# ESP32-S31 register map
Vendor: ESPRESSIF SYSTEMS (SHANGHAI) CO., LTD.; Series: ESP32 S-Series; File version: 1
CPU: RV32IMAFC r0p0, little endian, no MPU, FPU, 0 interrupt priority bits
Address unit: 32 bits
Registers are 32-bit, read-write, reset 0x0 unless marked. A register's access mark holds for its fields unless they carry their own. Offsets are from the block's base; [hi:lo] are bit positions; {n}, {i} and the like mark numbered series.

## SPI0 (part 2 of 2) — SPI (Serial Peripheral Interface) Controller 0
Base 0x20500000
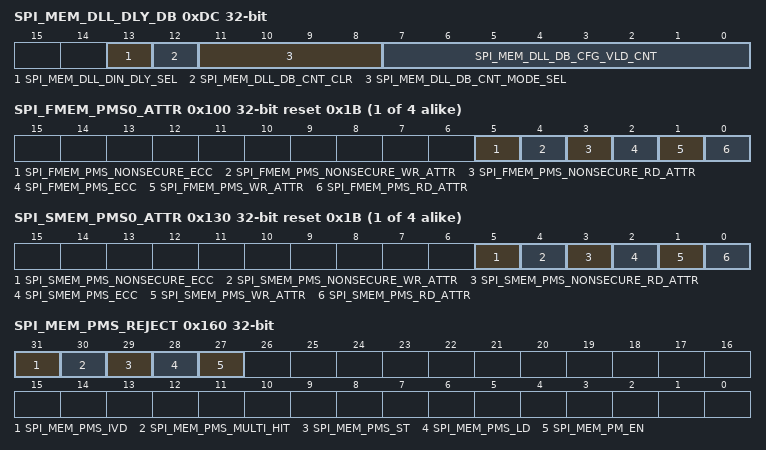
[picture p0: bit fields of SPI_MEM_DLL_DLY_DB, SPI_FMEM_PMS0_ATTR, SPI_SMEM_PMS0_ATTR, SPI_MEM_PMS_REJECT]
0xDC SPI_MEM_DLL_DLY_DB — MSPI DLL function and debug configuration register
  [13] SPI_MEM_DLL_DIN_DLY_SEL — Configures the din channel. 1: Use delayed data. 0: Do not use delayed data.
  [12] SPI_MEM_DLL_DB_CNT_CLR — Configures the start time of the debug window. 1: Clear db_vld_cnt to 0 and Get ready for debug. 0: No debug.
  [11:8] SPI_MEM_DLL_DB_CNT_MODE_SEL — [3]:1-spi_din[15:8]. 0-spi_din[7:0]. [2]:1-only shift wptr or rptr. 0-both shft wptr and rptr. [1]:1-wprt[3:0] and rptr[3:0]. 0-rptr[3:0] and wprt[3:0]. [0]:1-neg_ptr[3:0]. 0-pos_prt[3:0].
  [7:0] SPI_MEM_DLL_DB_CFG_VLD_CNT — Configures the end time of the debug window.
0xE0 SPI_MEM_DLL_DB_ST0 ro — MSPI DLL debug status0 register
  [31:0] SPI_MEM_DB_FIFO_CNT_H — Debug for DLL FIFO pointer. Use a 64bits shift register to record pointer changes during the debug window. db_fifo_cnt[63:32]
0xE4 SPI_MEM_DLL_DB_ST1 ro — MSPI DLL debug status1 register
  [31:0] SPI_MEM_DB_FIFO_CNT_L — Debug for DLL FIFO pointer. Use a 64bits shift register to record pointer changes during the debug window. db_fifo_cnt[31:0]
{0x100+4i} SPI_FMEM_PMS{i}_ATTR (i=0..3) reset 0x1B — SPI1 flash PMS section {i} attribute register
  [5] SPI_FMEM_PMS_NONSECURE_ECC — SPI1 flash non-secure PMS section %s ECC mode, 1: enable ECC mode. 0: Disable it. The flash PMS section %s is configured by registers SPI_FMEM_PMS%s_ADDR_REG and SPI_FMEM_PMS%s_SIZE_REG.
  [4] SPI_FMEM_PMS_NONSECURE_WR_ATTR — 1: SPI1 flash non-secure PMS section %s write accessible. 0: Not allowed.
  [3] SPI_FMEM_PMS_NONSECURE_RD_ATTR — 1: SPI1 flash non-secure PMS section %s read accessible. 0: Not allowed.
  [2] SPI_FMEM_PMS_ECC — SPI1 flash PMS section %s ECC mode, 1: enable ECC mode. 0: Disable it. The flash PMS section %s is configured by registers SPI_FMEM_PMS%s_ADDR_REG and SPI_FMEM_PMS%s_SIZE_REG.
  [1] SPI_FMEM_PMS_WR_ATTR — 1: SPI1 flash PMS section %s write accessible. 0: Not allowed.
  [0] SPI_FMEM_PMS_RD_ATTR — 1: SPI1 flash PMS section %s read accessible. 0: Not allowed.
{0x110+4i} SPI_FMEM_PMS{i}_ADDR (i=0..3) — SPI1 flash PMS section {i} start address register
  [28:0] S — SPI1 flash PMS section %s start address value
{0x120+4i} SPI_FMEM_PMS{i}_SIZE (i=0..3) reset 0x1000 — SPI1 flash PMS section {i} start address register
  [16:0] SPI_FMEM_PMS_SIZE — SPI1 flash PMS section %s address region is (SPI_FMEM_PMS%s_ADDR_S, SPI_FMEM_PMS%s_ADDR_S + SPI_FMEM_PMS%s_SIZE)
{0x130+4i} SPI_SMEM_PMS{i}_ATTR (i=0..3) reset 0x1B — SPI1 external RAM PMS section {i} attribute register
  [5] SPI_SMEM_PMS_NONSECURE_ECC — SPI1 external RAM non-secure PMS section %s ECC mode, 1: enable ECC mode. 0: Disable it. The external RAM PMS section %s is configured by registers SPI_SMEM_PMS%s_ADDR_REG and SPI_SMEM_PMS%s_SIZE_REG.
  [4] SPI_SMEM_PMS_NONSECURE_WR_ATTR — 1: SPI1 external RAM non-secure PMS section %s write accessible. 0: Not allowed.
  [3] SPI_SMEM_PMS_NONSECURE_RD_ATTR — 1: SPI1 external RAM non-secure PMS section %s read accessible. 0: Not allowed.
  [2] SPI_SMEM_PMS_ECC — SPI1 external RAM PMS section %s ECC mode, 1: enable ECC mode. 0: Disable it. The external RAM PMS section %s is configured by registers SPI_SMEM_PMS%s_ADDR_REG and SPI_SMEM_PMS%s_SIZE_REG.
  [1] SPI_SMEM_PMS_WR_ATTR — 1: SPI1 external RAM PMS section %s write accessible. 0: Not allowed.
  [0] SPI_SMEM_PMS_RD_ATTR — 1: SPI1 external RAM PMS section %s read accessible. 0: Not allowed.
{0x140+4i} SPI_SMEM_PMS{i}_ADDR (i=0..3) — SPI1 external RAM PMS section {i} start address register
  [28:0] S — SPI1 external RAM PMS section %s start address value
{0x150+4i} SPI_SMEM_PMS{i}_SIZE (i=0..3) reset 0x1000 — SPI1 external RAM PMS section {i} start address register
  [16:0] SPI_SMEM_PMS_SIZE — SPI1 external RAM PMS section %s address region is (SPI_SMEM_PMS%s_ADDR_S, SPI_SMEM_PMS%s_ADDR_S + SPI_SMEM_PMS%s_SIZE)
0x160 SPI_MEM_PMS_REJECT access per field — SPI1 access reject register
  [31] SPI_MEM_PMS_IVD ro — 1: SPI1 access is rejected because of address multi-hit. 0: No address multi-hit error. It is cleared by when SPI_MEM_PMS_REJECT_INT_CLR bit is set.
  [30] SPI_MEM_PMS_MULTI_HIT ro — 1: SPI1 access is rejected because of address miss. 0: No address miss error. It is cleared by when SPI_MEM_PMS_REJECT_INT_CLR bit is set.
  [29] SPI_MEM_PMS_ST ro — 1: SPI1 read access error. 0: No read access error. It is cleared by when SPI_MEM_PMS_REJECT_INT_CLR bit is set.
  [28] SPI_MEM_PMS_LD ro — 1: SPI1 write access error. 0: No write access error. It is cleared by when SPI_MEM_PMS_REJECT_INT_CLR bit is set.
  [27] SPI_MEM_PM_EN rw — Set this bit to enable SPI0/1 transfer permission control function.
0x164 SPI_MEM_PMS_REJECT_ADDR ro — SPI1 access reject addr register
  [28:0] SPI_MEM_REJECT_ADDR — This bits show the first SPI1 access error address. It is cleared by when SPI_MEM_PMS_REJECT_INT_CLR bit is set.
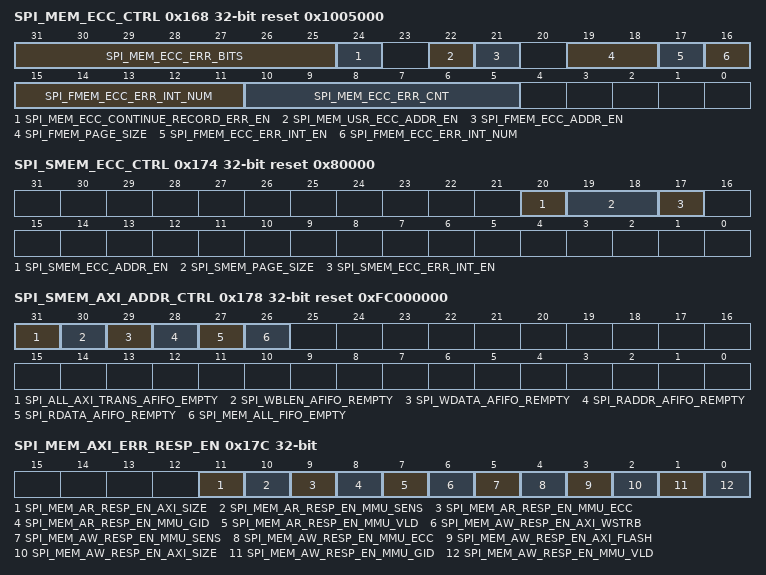
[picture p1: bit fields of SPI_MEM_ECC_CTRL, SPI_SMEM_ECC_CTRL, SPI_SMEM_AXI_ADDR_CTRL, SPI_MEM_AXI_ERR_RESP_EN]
0x168 SPI_MEM_ECC_CTRL access per field reset 0x1005000 — MSPI ECC control register
  [31:25] SPI_MEM_ECC_ERR_BITS ro — Records the first ECC error bit number in the 16 bytes(From 0~127, corresponding to byte 0 bit 0 to byte 15 bit 7)
  [24] SPI_MEM_ECC_CONTINUE_RECORD_ERR_EN rw — 1: The error information in SPI_MEM_ECC_ERR_BITS and SPI_MEM_ECC_ERR_ADDR is updated when there is an ECC error. 0: SPI_MEM_ECC_ERR_BITS and SPI_MEM_ECC_ERR_ADDR record the first ECC error information.
  [22] SPI_MEM_USR_ECC_ADDR_EN rw — Set this bit to enable ECC address convert in SPI0/1 USR_CMD transfer.
  [21] SPI_FMEM_ECC_ADDR_EN rw — Set this bit to enable MSPI ECC address conversion, no matter MSPI accesses to the ECC region or non-ECC region of flash. If there is no ECC region in flash, this bit should be 0. Otherwise, this bit should be 1.
  [19:18] SPI_FMEM_PAGE_SIZE rw — Set the page size of the flash accessed by MSPI. 0: 256 bytes. 1: 512 bytes. 2: 1024 bytes. 3: 2048 bytes.
  [17] SPI_FMEM_ECC_ERR_INT_EN rw — Set this bit to calculate the error times of MSPI ECC read when accesses to flash.
  [16:11] SPI_FMEM_ECC_ERR_INT_NUM rw — Set the error times of MSPI ECC read to generate MSPI SPI_MEM_ECC_ERR_INT interrupt.
  [10:5] SPI_MEM_ECC_ERR_CNT ro — This bits show the error times of MSPI ECC read. It is cleared by when SPI_MEM_ECC_ERR_INT_CLR bit is set.
0x16C SPI_MEM_ECC_ERR_ADDR ro — MSPI ECC error address register
  [28:0] SPI_MEM_ECC_ERR_ADDR — This bits show the first MSPI ECC error address. It is cleared by when SPI_MEM_ECC_ERR_INT_CLR bit is set.
0x170 SPI_MEM_AXI_ERR_ADDR ro — SPI0 AXI request error address.
  [28:0] SPI_MEM_AXI_ERR_ADDR — This bits show the first AXI write/read invalid error or AXI write flash error address. It is cleared by when SPI_MEM_AXI_WADDR_ERR_INT_CLR, SPI_MEM_AXI_WR_FLASH_ERR_IN_CLR or SPI_MEM_AXI_RADDR_ERR_IN_CLR bit is set.
0x174 SPI_SMEM_ECC_CTRL reset 0x80000 — MSPI ECC control register
  [20] SPI_SMEM_ECC_ADDR_EN — Set this bit to enable MSPI ECC address conversion, no matter MSPI accesses to the ECC region or non-ECC region of external RAM. If there is no ECC region in external RAM, this bit should be 0. Otherwise, this bit should be 1.
  [19:18] SPI_SMEM_PAGE_SIZE — Set the page size of the external RAM accessed by MSPI. 0: 256 bytes. 1: 512 bytes. 2: 1024 bytes. 3: 2048 bytes.
  [17] SPI_SMEM_ECC_ERR_INT_EN — Set this bit to calculate the error times of MSPI ECC read when accesses to external RAM.
0x178 SPI_SMEM_AXI_ADDR_CTRL ro reset 0xFC000000 — SPI0 AXI address control register
  [31] SPI_ALL_AXI_TRANS_AFIFO_EMPTY — This bit is set when WADDR_AFIFO, WBLEN_AFIFO, WDATA_AFIFO, AXI_RADDR_CTL_AFIFO and RDATA_AFIFO are empty and spi0_mst_st is IDLE.
  [30] SPI_WBLEN_AFIFO_REMPTY — 1: WBLEN_AFIFO is empty. 0: At least one AXI write transfer is pending.
  [29] SPI_WDATA_AFIFO_REMPTY — 1: WDATA_AFIFO is empty. 0: At least one AXI write transfer is pending.
  [28] SPI_RADDR_AFIFO_REMPTY — 1: AXI_RADDR_CTL_AFIFO is empty. 0: At least one AXI read transfer is pending.
  [27] SPI_RDATA_AFIFO_REMPTY — 1: RDATA_AFIFO is empty. 0: At least one AXI read transfer is pending.
  [26] SPI_MEM_ALL_FIFO_EMPTY — The empty status of all AFIFO and SYNC_FIFO in MSPI module. 1: All AXI transfers and SPI0 transfers are done. 0: Others.
0x17C SPI_MEM_AXI_ERR_RESP_EN — SPI0 AXI error response enable register
  [11] SPI_MEM_AR_RESP_EN_AXI_SIZE — Set this bit to enable AXI response function for axi size err in axi read trans.
  [10] SPI_MEM_AR_RESP_EN_MMU_SENS — Set this bit to enable AXI response function for mmu sensitive err in axi read trans.
  [9] SPI_MEM_AR_RESP_EN_MMU_ECC — Set this bit to enable AXI response function for mmu ecc err in axi read trans.
  [8] SPI_MEM_AR_RESP_EN_MMU_GID — Set this bit to enable AXI response function for mmu gid err in axi read trans.
  [7] SPI_MEM_AR_RESP_EN_MMU_VLD — Set this bit to enable AXI response function for mmu valid err in axi read trans.
  [6] SPI_MEM_AW_RESP_EN_AXI_WSTRB — Set this bit to enable AXI response function for axi wstrb err in axi write trans.
  [5] SPI_MEM_AW_RESP_EN_MMU_SENS — Set this bit to enable AXI response function for mmu sens in err axi write trans.
  [4] SPI_MEM_AW_RESP_EN_MMU_ECC — Set this bit to enable AXI response function for mmu ecc err in axi write trans.
  [3] SPI_MEM_AW_RESP_EN_AXI_FLASH — Set this bit to enable AXI response function for axi flash err in axi write trans.
  [2] SPI_MEM_AW_RESP_EN_AXI_SIZE — Set this bit to enable AXI response function for axi size err in axi write trans.
  [1] SPI_MEM_AW_RESP_EN_MMU_GID — Set this bit to enable AXI response function for mmu gid err in axi write trans.
  [0] SPI_MEM_AW_RESP_EN_MMU_VLD — Set this bit to enable AXI response function for mmu valid err in axi write trans.
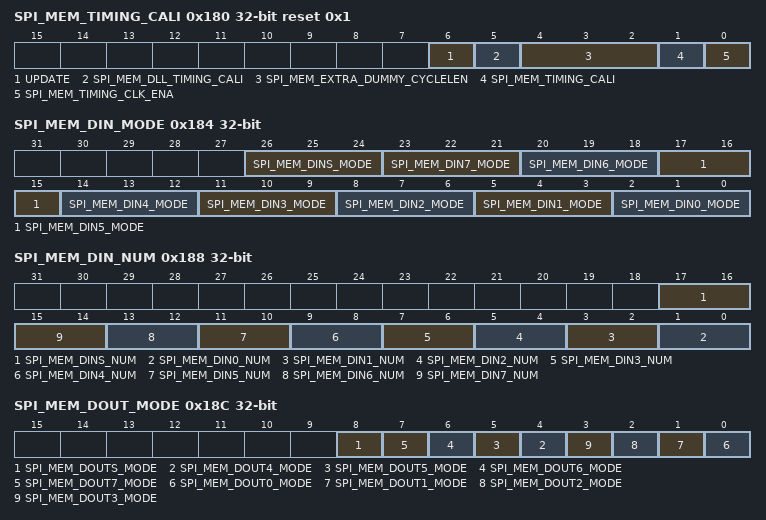
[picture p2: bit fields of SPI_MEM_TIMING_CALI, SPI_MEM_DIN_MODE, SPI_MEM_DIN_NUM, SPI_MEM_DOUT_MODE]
0x180 SPI_MEM_TIMING_CALI access per field reset 0x1 — SPI0 flash timing calibration register
  [6] UPDATE wo — Set this bit to update delay mode, delay num and extra dummy in MSPI.
  [5] SPI_MEM_DLL_TIMING_CALI rw — Set this bit to enable DLL for timing calibration in DDR mode when accessed to flash.
  [4:2] SPI_MEM_EXTRA_DUMMY_CYCLELEN rw — add extra dummy spi clock cycle length for spi clock calibration.
  [1] SPI_MEM_TIMING_CALI rw — The bit is used to enable timing auto-calibration for all reading operations.
  [0] SPI_MEM_TIMING_CLK_ENA rw — The bit is used to enable timing adjust clock for all reading operations.
0x184 SPI_MEM_DIN_MODE — MSPI flash input timing delay mode control register
  [26:24] SPI_MEM_DINS_MODE — the input signals are delayed by system clock cycles, 0: input without delayed, 1: input with the posedge of clk_apb,2 input with the negedge of clk_apb, 3: input with the spi_clk
  [3n+2:3n] SPI_MEM_DIN{n}_MODE (n=4..7) — the input signals are delayed by system clock cycles, 0: input without delayed, 1: input with the posedge of clk_apb,2 input with the negedge of clk_apb, 3: input with the spi_clk
  [3n+2:3n] SPI_MEM_DIN{n}_MODE (n=0..3) — the input signals are delayed by system clock cycles, 0: input without delayed, 1: input with the posedge of clk_apb,2 input with the negedge of clk_apb, 3: input with the posedge of clk_160, 4 input with the negedge of clk_160, 5: input with the spi_clk high edge, 6: input with the spi_clk low edge
0x188 SPI_MEM_DIN_NUM — MSPI flash input timing delay number control register
  [17:16] SPI_MEM_DINS_NUM — the input signals are delayed by system clock cycles, 0: delayed by 1 cycle, 1: delayed by 2 cycles,...
  [2n+1:2n] SPI_MEM_DIN{n}_NUM (n=0..7) — the input signals are delayed by system clock cycles, 0: delayed by 1 cycle, 1: delayed by 2 cycles,...
0x18C SPI_MEM_DOUT_MODE — MSPI flash output timing adjustment control register
  [8] SPI_MEM_DOUTS_MODE — the output signals are delayed by system clock cycles, 0: output without delayed, 1: output with the posedge of clk_apb,2 output with the negedge of clk_apb, 3: output with the spi_clk
  [n] SPI_MEM_DOUT{n}_MODE (n=4..7) — the output signals are delayed by system clock cycles, 0: output without delayed, 1: output with the posedge of clk_apb,2 output with the negedge of clk_apb, 3: output with the spi_clk
  [n] SPI_MEM_DOUT{n}_MODE (n=0..3) — the output signals are delayed by system clock cycles, 0: output without delayed, 1: output with the posedge of clk_apb,2 output with the negedge of clk_apb, 3: output with the posedge of clk_160,4 output with the negedge of clk_160,5: output with the spi_clk high edge ,6: output with the spi_clk low edge
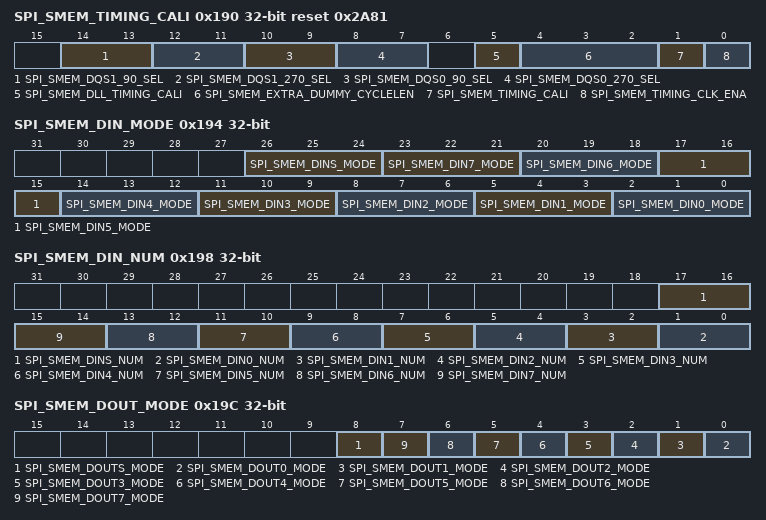
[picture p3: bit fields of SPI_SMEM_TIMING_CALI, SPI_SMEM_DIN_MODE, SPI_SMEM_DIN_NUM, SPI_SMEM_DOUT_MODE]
0x190 SPI_SMEM_TIMING_CALI reset 0x2A81 — MSPI external RAM timing calibration register
  [14:13] SPI_SMEM_DQS1_90_SEL — Set these bits to delay dqs signal for DLL timing adjust. 2'd0: 0.5ns, 2'd1: 1.0ns, 2'd2: 1.5ns 2'd3: 2.0ns.
  [12:11] SPI_SMEM_DQS1_270_SEL — Set these bits to delay dqs signal & invert delayed signal for DLL timing adjust. 2'd0: 0.5ns, 2'd1: 1.0ns, 2'd2: 1.5ns 2'd3: 2.0ns.
  [10:9] SPI_SMEM_DQS0_90_SEL — Set these bits to delay dqs signal for DLL timing adjust. 2'd0: 0.5ns, 2'd1: 1.0ns, 2'd2: 1.5ns 2'd3: 2.0ns.
  [8:7] SPI_SMEM_DQS0_270_SEL — Set these bits to delay dqs signal & invert delayed signal for DLL timing adjust. 2'd0: 0.5ns, 2'd1: 1.0ns, 2'd2: 1.5ns 2'd3: 2.0ns.
  [5] SPI_SMEM_DLL_TIMING_CALI — Set this bit to enable DLL for timing calibration in DDR mode when accessed to EXT_RAM.
  [4:2] SPI_SMEM_EXTRA_DUMMY_CYCLELEN — For sram, add extra dummy spi clock cycle length for spi clock calibration.
  [1] SPI_SMEM_TIMING_CALI — For sram, the bit is used to enable timing auto-calibration for all reading operations.
  [0] SPI_SMEM_TIMING_CLK_ENA — For sram, the bit is used to enable timing adjust clock for all reading operations.
0x194 SPI_SMEM_DIN_MODE — MSPI external RAM input timing delay mode control register
  [26:24] SPI_SMEM_DINS_MODE — the input signals are delayed by system clock cycles, 0: input without delayed, 1: input with the posedge of clk_apb,2 input with the negedge of clk_apb, 3: input with the posedge of clk_160, 4 input with the negedge of clk_160, 5: input with the spi_clk high edge, 6: input with the spi_clk low edge
  [3n+2:3n] SPI_SMEM_DIN{n}_MODE (n=0..7) — the input signals are delayed by system clock cycles, 0: input without delayed, 1: input with the posedge of clk_apb,2 input with the negedge of clk_apb, 3: input with the posedge of clk_160, 4 input with the negedge of clk_160, 5: input with the spi_clk high edge, 6: input with the spi_clk low edge
0x198 SPI_SMEM_DIN_NUM — MSPI external RAM input timing delay number control register
  [17:16] SPI_SMEM_DINS_NUM — the input signals are delayed by system clock cycles, 0: delayed by 1 cycle, 1: delayed by 2 cycles,...
  [2n+1:2n] SPI_SMEM_DIN{n}_NUM (n=0..7) — the input signals are delayed by system clock cycles, 0: delayed by 1 cycle, 1: delayed by 2 cycles,...
0x19C SPI_SMEM_DOUT_MODE — MSPI external RAM output timing adjustment control register
  [8] SPI_SMEM_DOUTS_MODE — the output signals are delayed by system clock cycles, 0: output without delayed, 1: output with the posedge of clk_apb,2 output with the negedge of clk_apb, 3: output with the posedge of clk_160,4 output with the negedge of clk_160,5: output with the spi_clk high edge ,6: output with the spi_clk low edge
  [n] SPI_SMEM_DOUT{n}_MODE (n=0..7) — the output signals are delayed by system clock cycles, 0: output without delayed, 1: output with the posedge of clk_apb,2 output with the negedge of clk_apb, 3: output with the posedge of clk_160,4 output with the negedge of clk_160,5: output with the spi_clk high edge ,6: output with the spi_clk low edge
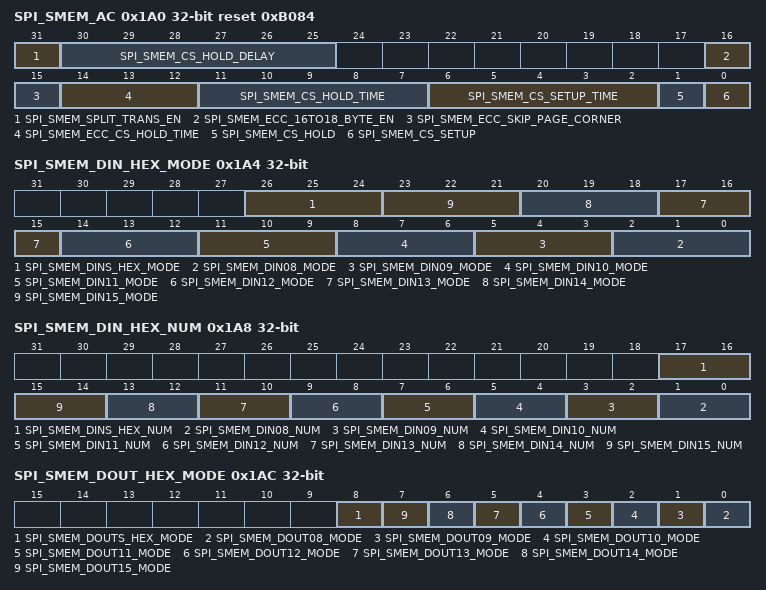
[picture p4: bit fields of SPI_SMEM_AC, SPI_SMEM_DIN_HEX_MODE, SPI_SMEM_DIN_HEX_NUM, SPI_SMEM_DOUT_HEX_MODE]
0x1A0 SPI_SMEM_AC reset 0xB084 — MSPI external RAM ECC and SPI CS timing control register
  [31] SPI_SMEM_SPLIT_TRANS_EN — Set this bit to enable SPI0 split one AXI accesses EXT_RAM transfer into two SPI transfers when one transfer will cross flash/EXT_RAM page corner, valid no matter whether there is an ECC region or not.
  [30:25] SPI_SMEM_CS_HOLD_DELAY — These bits are used to set the minimum CS high time tSHSL between SPI burst transfer when accesses to external RAM. tSHSL is (SPI_SMEM_CS_HOLD_DELAY[5:0] + 1) MSPI core clock cycles.
  [16] SPI_SMEM_ECC_16TO18_BYTE_EN — Set this bit to enable SPI0 and SPI1 ECC 16 bytes data with 2 ECC bytes mode when accesses external RAM.
  [15] SPI_SMEM_ECC_SKIP_PAGE_CORNER — 1: SPI0 skips page corner when accesses external RAM. 0: Not skip page corner when accesses external RAM.
  [14:12] SPI_SMEM_ECC_CS_HOLD_TIME — SPI_SMEM_CS_HOLD_TIME + SPI_SMEM_ECC_CS_HOLD_TIME is the SPI0 and SPI1 CS hold cycles in ECC mode when accessed external RAM.
  [11:7] SPI_SMEM_CS_HOLD_TIME — For SPI0 and SPI1, spi cs signal is delayed to inactive by spi clock this bits are combined with spi_mem_cs_hold bit.
  [6:2] SPI_SMEM_CS_SETUP_TIME — For spi0, (cycles-1) of prepare phase by spi clock this bits are combined with spi_mem_cs_setup bit.
  [1] SPI_SMEM_CS_HOLD — For SPI0 and SPI1, spi cs keep low when spi is in done phase. 1: enable 0: disable.
  [0] SPI_SMEM_CS_SETUP — For SPI0 and SPI1, spi cs is enable when spi is in prepare phase. 1: enable 0: disable.
0x1A4 SPI_SMEM_DIN_HEX_MODE — MSPI 16x external RAM input timing delay mode control register
  [26:24] SPI_SMEM_DINS_HEX_MODE — the input signals are delayed by system clock cycles, 0: input without delayed, 1: input with the posedge of clk_apb,2 input with the negedge of clk_apb, 3: input with the posedge of clk_160, 4 input with the negedge of clk_160, 5: input with the spi_clk high edge, 6: input with the spi_clk low edge
  [3n-22:3n-24] SPI_SMEM_DIN{n:02}_MODE (n=8..15) — the input signals are delayed by system clock cycles, 0: input without delayed, 1: input with the posedge of clk_apb,2 input with the negedge of clk_apb, 3: input with the posedge of clk_160, 4 input with the negedge of clk_160, 5: input with the spi_clk high edge, 6: input with the spi_clk low edge
0x1A8 SPI_SMEM_DIN_HEX_NUM — MSPI 16x external RAM input timing delay number control register
  [17:16] SPI_SMEM_DINS_HEX_NUM — the input signals are delayed by system clock cycles, 0: delayed by 1 cycle, 1: delayed by 2 cycles,...
  [2n-15:2n-16] SPI_SMEM_DIN{n:02}_NUM (n=8..15) — the input signals are delayed by system clock cycles, 0: delayed by 1 cycle, 1: delayed by 2 cycles,...
0x1AC SPI_SMEM_DOUT_HEX_MODE — MSPI 16x external RAM output timing adjustment control register
  [8] SPI_SMEM_DOUTS_HEX_MODE — the output signals are delayed by system clock cycles, 0: output without delayed, 1: output with the posedge of clk_apb,2 output with the negedge of clk_apb, 3: output with the posedge of clk_160,4 output with the negedge of clk_160,5: output with the spi_clk high edge ,6: output with the spi_clk low edge
  [n-8] SPI_SMEM_DOUT{n:02}_MODE (n=8..15) — the output signals are delayed by system clock cycles, 0: output without delayed, 1: output with the posedge of clk_apb,2 output with the negedge of clk_apb, 3: output with the posedge of clk_160,4 output with the negedge of clk_160,5: output with the spi_clk high edge ,6: output with the spi_clk low edge
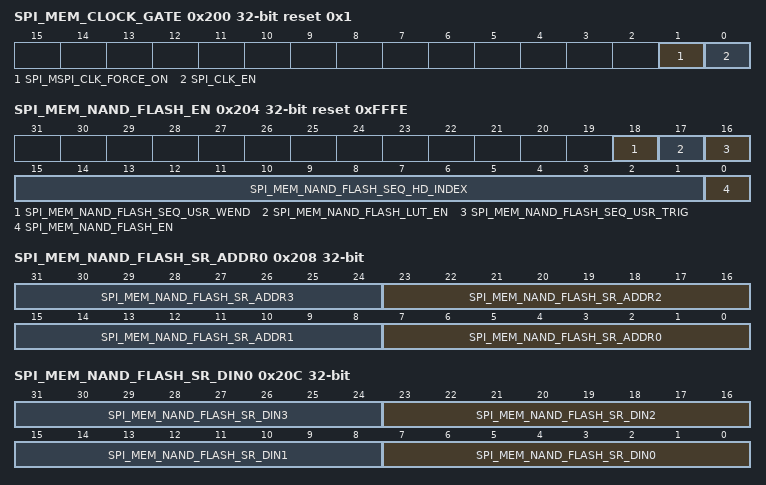
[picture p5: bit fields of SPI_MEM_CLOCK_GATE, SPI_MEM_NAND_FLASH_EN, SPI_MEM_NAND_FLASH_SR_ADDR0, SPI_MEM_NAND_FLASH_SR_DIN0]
0x200 SPI_MEM_CLOCK_GATE reset 0x1 — SPI0 clock gate register
  [1] SPI_MSPI_CLK_FORCE_ON — MSPI lowpower function clock gate force on signal. 1: Enable. 0: Disable.
  [0] SPI_CLK_EN — Register clock gate enable signal. 1: Enable. 0: Disable.
0x204 SPI_MEM_NAND_FLASH_EN ro reset 0xFFFE — NAND FLASH control register
  [18] SPI_MEM_NAND_FLASH_SEQ_USR_WEND — Used with SPI_MEM_NAND_FLASH_SEQ_USR_TRIG to indecate the last page program ,and to excute page excute. 1: write end 0: write in a page size.
  [17] SPI_MEM_NAND_FLASH_LUT_EN — NAND FLASH spi seq & cmd lut cfg en. 1: enable 0: disable.
  [16] SPI_MEM_NAND_FLASH_SEQ_USR_TRIG — NAND FLASH spi seq user trigger configure register. SPI_MEM_NAND_FLASH_SEQ_USR_TRIG is corresponds to SPI_MEM_NAND_FLASH_SEQ_HD_INDEX[14:10].1: enable 0: disable.
  [15:1] SPI_MEM_NAND_FLASH_SEQ_HD_INDEX — NAND FLASH spi seq head index configure register. Every 5 bits represent the 1st index of a SPI CMD sequence.[14:10]:usr; [9:5]:axi_rd; [4:0]:axi_wr.
  [0] SPI_MEM_NAND_FLASH_EN — NAND FLASH function enable signal. 1: Enable NAND FLASH, Disable NOR FLASH. 0: Disable NAND FLASH, Enable NOR FLASH.
0x208 SPI_MEM_NAND_FLASH_SR_ADDR0 ro — NAND FLASH SPI SEQ control register
  [8n+7:8n] SPI_MEM_NAND_FLASH_SR_ADDR{n} (n=0..3) — configure state register address for SPI SEQ need. If OIP is in address C0H , user could configure C0H into this register
0x20C SPI_MEM_NAND_FLASH_SR_DIN0 ro — NAND FLASH SPI SEQ control register
  [8n+7:8n] SPI_MEM_NAND_FLASH_SR_DIN{n} (n=0..3) — spi read state register data to this register for SPI SEQ need. SPI_MEM_NAND_FLASH_SR_DIN0_REG corresponds to SPI_MEM_NAND_FLASH_SR_ADDR0_REG.
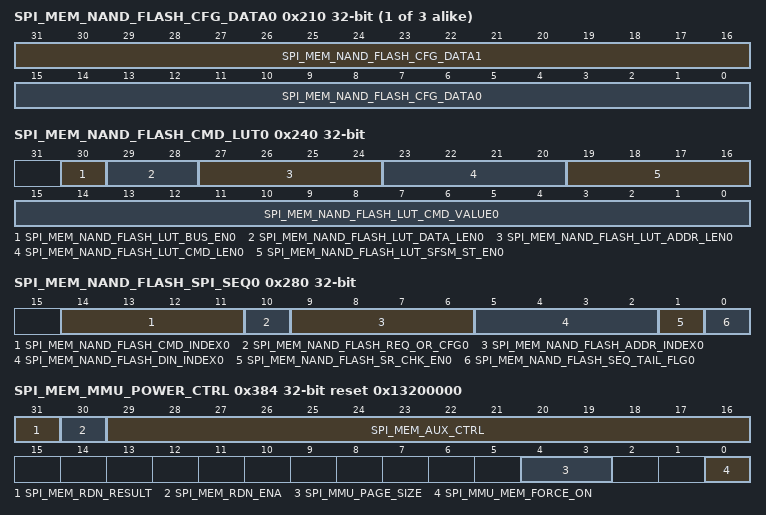
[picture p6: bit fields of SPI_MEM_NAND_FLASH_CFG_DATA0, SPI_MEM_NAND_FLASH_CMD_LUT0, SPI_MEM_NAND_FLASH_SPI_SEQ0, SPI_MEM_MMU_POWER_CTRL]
{0x210+4i} SPI_MEM_NAND_FLASH_CFG_DATA{i} ro (i=0..2) — NAND FLASH SPI SEQ control register
  [31:16] SPI_MEM_NAND_FLASH_CFG_DATA{2i+1} — configure data for SPI SEQ din/dout need. The data could be use to configure NAND FLASH or compare read data
  [15:0] SPI_MEM_NAND_FLASH_CFG_DATA{2i} — configure data for SPI SEQ din/dout need. The data could be use to configure NAND FLASH or compare read data
0x240 SPI_MEM_NAND_FLASH_CMD_LUT0 ro — MSPI NAND FLASH CMD LUT control register
  [30] SPI_MEM_NAND_FLASH_LUT_BUS_EN0 — MSPI NAND FLASH config spi_bus_en at cmd lut address 0,SPI could use DUAL/QUAD mode while enable, SPI could use SINGLE mode while disable.1:Enable. 0:Disable.(Note these registers are described to indicate the SPI_MEM_NAND_FLASH_CMD_LUT0_REG's field. The number of CMD LUT entries can be defined by the user, but cannot exceed 16 )
  [29:28] SPI_MEM_NAND_FLASH_LUT_DATA_LEN0 — MSPI NAND FLASH config data length at cmd lut address 0.
  [27:24] SPI_MEM_NAND_FLASH_LUT_ADDR_LEN0 — MSPI NAND FLASH config address length at cmd lut address 0.
  [23:20] SPI_MEM_NAND_FLASH_LUT_CMD_LEN0 — MSPI NAND FLASH config cmd length at cmd lut address 0.
  [19:16] SPI_MEM_NAND_FLASH_LUT_SFSM_ST_EN0 — MSPI NAND FLASH config sfsm_st_en at cmd lut address 0.[3]-ADDR period enable; [2]-DUMMY period enable; [1]-DIN period; [0]-DOUT period.
  [15:0] SPI_MEM_NAND_FLASH_LUT_CMD_VALUE0 — MSPI NAND FLASH config cmd value at cmd lut address 0.
0x280 SPI_MEM_NAND_FLASH_SPI_SEQ0 ro — NAND FLASH SPI SEQ control register
  [14:11] SPI_MEM_NAND_FLASH_CMD_INDEX0 — MSPI NAND FLASH config spi_cmd_index at spi seq index 0. Use to find SPI command in CMD LUT.(Note these registers are described to indicate the SPI_MEM_NAND_FLASH_SPI_SEQ_REG' fieldd The number of CMD LUT entries can be defined by the user, but cannot exceed 16 )
  [10] SPI_MEM_NAND_FLASH_REQ_OR_CFG0 — MSPI NAND FLASH config reg_or_cfg at spi seq index 0. 1: AXI/APB request 0: SPI SEQ configuration.
  [9:6] SPI_MEM_NAND_FLASH_ADDR_INDEX0 — MSPI NAND FLASH config addr_index at spi seq index 0. Use with SPI_MEM_NAND_FLASH_SR_ADDR
  [5:2] SPI_MEM_NAND_FLASH_DIN_INDEX0 — MSPI NAND FLASH config din_index at spi seq index 0. Use with SPI_MEM_NAND_FLASH_CFG_DATA
  [1] SPI_MEM_NAND_FLASH_SR_CHK_EN0 — MSPI NAND FLASH config sr_chk_en at spi seq index 0. 1: enable 0: disable.
  [0] SPI_MEM_NAND_FLASH_SEQ_TAIL_FLG0 — MSPI NAND FLASH config seq_tail_flg at spi seq index 0.1: The last index for sequence. 0: Not the last index.
0x300 SPI_MEM_XTS_PLAIN_BASE — The base address of the memory that stores plaintext in Manual Encryption
  [31:0] SPI_XTS_PLAIN — This field is only used to generate include file in c case. This field is useless. Please do not use this field.
0x340 SPI_MEM_XTS_LINESIZE — Manual Encryption Line-Size register
  [1:0] SPI_XTS_LINESIZE — This bits stores the line-size parameter which will be used in manual encryption calculation. It decides how many bytes will be encrypted one time. 0: 16-bytes, 1: 32-bytes, 2: 64-bytes, 3:reserved.
0x344 SPI_MEM_XTS_DESTINATION — Manual Encryption destination register
  [0] SPI_XTS_DESTINATION — This bit stores the destination parameter which will be used in manual encryption calculation. 0: flash(default), 1: psram(reserved). Only default value can be used.
0x348 SPI_MEM_XTS_PHYSICAL_ADDRESS — Manual Encryption physical address register
  [29:0] SPI_XTS_PHYSICAL_ADDRESS — This bits stores the physical-address parameter which will be used in manual encryption calculation. This value should aligned with byte number decided by line-size parameter.
0x34C SPI_MEM_XTS_TRIGGER wo — Manual Encryption physical address register
  [0] SPI_XTS_TRIGGER — Set this bit to trigger the process of manual encryption calculation. This action should only be asserted when manual encryption status is 0. After this action, manual encryption status becomes 1. After calculation is done, manual encryption status becomes 2.
0x350 SPI_MEM_XTS_RELEASE wo — Manual Encryption physical address register
  [0] SPI_XTS_RELEASE — Set this bit to release encrypted result to mspi. This action should only be asserted when manual encryption status is 2. After this action, manual encryption status will become 3.
0x354 SPI_MEM_XTS_DESTROY wo — Manual Encryption physical address register
  [0] SPI_XTS_DESTROY — Set this bit to destroy encrypted result. This action should be asserted only when manual encryption status is 3. After this action, manual encryption status will become 0.
0x358 SPI_MEM_XTS_STATE ro — Manual Encryption physical address register
  [1:0] SPI_XTS_STATE — This bits stores the status of manual encryption. 0: idle, 1: busy of encryption calculation, 2: encryption calculation is done but the encrypted result is invisible to mspi, 3: the encrypted result is visible to mspi.
0x35C SPI_MEM_XTS_DATE reset 0x20210907 — Manual Encryption version register
  [29:0] SPI_XTS_DATE — This bits stores the last modified-time of manual encryption feature.
0x37C MMU_ITEM_CONTENT reset 0x37C — MSPI-MMU item content register
  [13] SENSITIVE — Decrypt via flash encryption when set (flash MMU)
  [12] VALID — Entry is valid when set (flash MMU)
  [12] SPIRAM_SENSITIVE — Decrypt via cache encryption when set (SPIRAM MMU)
  [11] SPIRAM_VALID — Entry is valid when set (SPIRAM MMU)
  [10] ACCESS_SPIRAM — Map to SPIRAM/PSRAM when set (flash when clear)
  [9:0] PADDR — Physical page number
0x380 SPI_MEM_MMU_ITEM_INDEX — MSPI-MMU item index register
  [31:0] SPI_MMU_ITEM_INDEX — MSPI-MMU item index
0x384 SPI_MEM_MMU_POWER_CTRL access per field reset 0x13200000 — MSPI MMU power control register
  [31] SPI_MEM_RDN_RESULT ro — MSPI module clock domain and AXI clock domain ECO register result register
  [30] SPI_MEM_RDN_ENA rw — ECO register enable bit
  [29:16] SPI_MEM_AUX_CTRL rw — MMU PSRAM aux control register
  [4:3] SPI_MMU_PAGE_SIZE rw — 0: Max page size , 1: Max page size/2 , 2: Max page size/4, 3: Max page size/8
  [0] SPI_MMU_MEM_FORCE_ON rw — Set this bit to enable mmu-memory clock force on
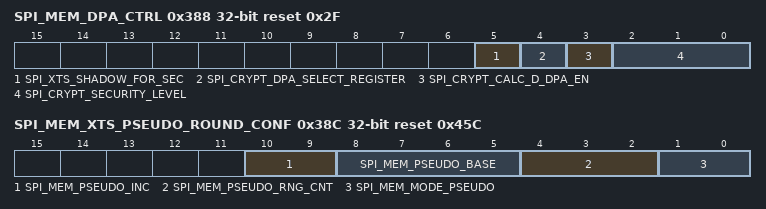
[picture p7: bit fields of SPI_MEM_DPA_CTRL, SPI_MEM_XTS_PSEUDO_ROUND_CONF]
0x388 SPI_MEM_DPA_CTRL reset 0x2F — SPI memory cryption DPA register
  [5] SPI_XTS_SHADOW_FOR_SEC — 1: shadow core mode for security (against fault injection attack). 0: shadow core mode for performance.
  [4] SPI_CRYPT_DPA_SELECT_REGISTER — 1: MSPI XTS DPA clock gate is controlled by SPI_CRYPT_CALC_D_DPA_EN and SPI_CRYPT_SECURITY_LEVEL. 0: Controlled by efuse bits.
  [3] SPI_CRYPT_CALC_D_DPA_EN — Only available when SPI_CRYPT_SECURITY_LEVEL is not 0. 1: Enable DPA in the calculation that using key 1 or key 2. 0: Enable DPA only in the calculation that using key 1.
  [2:0] SPI_CRYPT_SECURITY_LEVEL — Set the security level of spi mem cryption. 0: Shut off cryption DPA funtion. 1-7: The bigger the number is, the more secure the cryption is. (Note that the performance of cryption will decrease together with this number increasing)
0x38C SPI_MEM_XTS_PSEUDO_ROUND_CONF reset 0x45C — SPI memory cryption PSEUDO register
  [10:9] SPI_MEM_PSEUDO_INC — xts aes peseudo function increment round that will be peformed randomly between 0 & 2**(inc+1).
  [8:5] SPI_MEM_PSEUDO_BASE — xts aes peseudo function base round that must be peformed.
  [4:2] SPI_MEM_PSEUDO_RNG_CNT — xts aes peseudo function base round that must be peformed.
  [1:0] SPI_MEM_MODE_PSEUDO — Set the mode of pseudo. 2'b00: crypto without pseudo. 2'b01: state T with pseudo and state D without pseudo. 2'b10: state T with pseudo and state D with few pseudo. 2'b11: crypto with pseudo.
0x3F0 SPI_MEM_REGISTERRND_ECO_HIGH reset 0x37C — MSPI ECO high register
  [31:0] SPI_MEM_REGISTERRND_ECO_HIGH — ECO high register
0x3F4 SPI_MEM_REGISTERRND_ECO_LOW reset 0x37C — MSPI ECO low register
  [31:0] SPI_MEM_REGISTERRND_ECO_LOW — ECO low register
0x3FC SPI_MEM_DATE reset 0x2509030 — SPI0 version control register
  [27:0] SPI_MEM_DATE — SPI0 register version.
